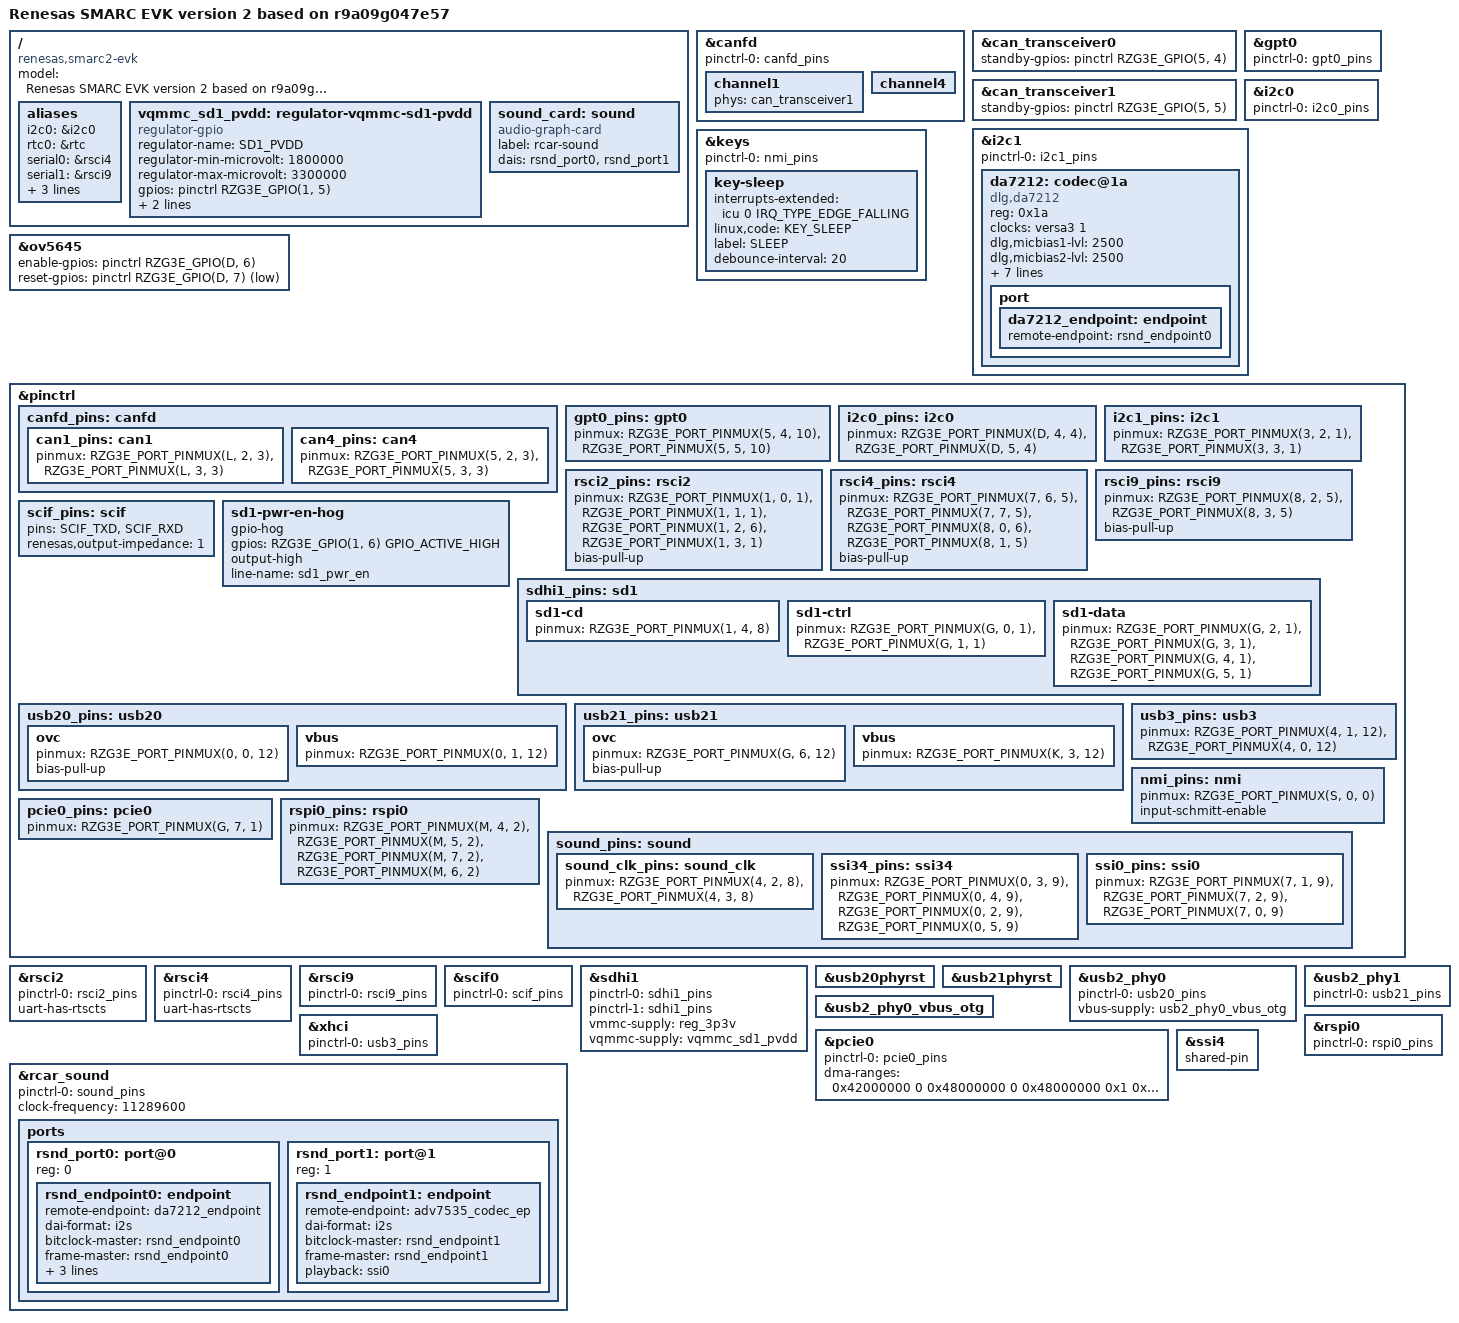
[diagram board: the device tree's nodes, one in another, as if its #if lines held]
// SPDX-License-Identifier: (GPL-2.0-only OR BSD-2-Clause)
/*
 * Device Tree Source for the RZ/G3E SMARC EVK board
 *
 * Copyright (C) 2024 Renesas Electronics Corp.
 */

/dts-v1/;

/* Switch selection settings */
#define SW_GPIO8_CAN0_STB	0
#define SW_GPIO9_CAN1_STB	0
#define SW_LCD_EN		0
#define SW_PDM_EN		0
#define SW_SER0_PMOD           1
#define SW_SER2_EN             1
#define SW_SD0_DEV_SEL		0
#define SW_SDIO_M2E		0
#define SW_HDMI_EN		0

#define PMOD_GPIO4		0
#define PMOD_GPIO6		0
#define PMOD_GPIO7		0

#define KEY_1_GPIO		RZG3E_GPIO(3, 1)
#define KEY_2_GPIO		RZG3E_GPIO(8, 4)
#define KEY_3_GPIO		RZG3E_GPIO(8, 5)

/*
 * Mode selection settings RSPI0_RSCI8_SEL:
 * 1 - RSCI8			0 - RSPI0 (default)
 */

#define RSPI0_RSCI8_SEL		0

/*
 * Display support selection:
 * 0 - disable display selection support
 * 1 - enable display selection support
 * for:
 * - MIPI DSI: RZG3E_SMARC_MIPI_DSI_ENABLE
 * - LVDS: RZG3E_SMARC_LVDS_ENABLE
 * - Parallel RGB: SW_LCD_EN from above switch selection settings
 */

#define RZG3E_SMARC_MIPI_DSI_ENABLE	1
#define RZG3E_SMARC_LVDS_ENABLE 	0

/* Only maximum 2 display selections are enabled at the same time */
#if (RZG3E_SMARC_MIPI_DSI_ENABLE & RZG3E_SMARC_LVDS_ENABLE & SW_LCD_EN)
#error "Only maximum 2 display selections are enabled at the same time"
#endif

#include <dt-bindings/gpio/gpio.h>
#include <dt-bindings/input/input.h>
#include <dt-bindings/pinctrl/renesas,r9a09g047-pinctrl.h>
#include "r9a09g047e57.dtsi"
#include "rzg3e-smarc-som.dtsi"
#include "renesas-smarc2.dtsi"

#define OV5645_PARENT_I2C i2c0
#include "rz-smarc-cru-csi-ov5645.dtsi"

#if (RZG3E_SMARC_LVDS_ENABLE)
#include "renesas-smarc2-dual-lvds-hdmi.dtsi"
#endif
#if (SW_LCD_EN)
#include "renesas-smarc2-rgb.dtsi"
#endif

/*
 * SSI-DA7212
 *
 * These commands are required when Playback/Capture
 *
 *	amixer -q cset name='Aux Switch' on
 *	amixer -q cset name='Mixin Left Aux Left Switch' on
 *	amixer -q cset name='Mixin Right Aux Right Switch' on
 *	amixer -q cset name='ADC Switch' on
 *	amixer -q cset name='Mixout Right Mixin Right Switch' off
 *	amixer -q cset name='Mixout Left Mixin Left Switch' off
 *	amixer -q cset name='Headphone Volume' 80%
 *	amixer -q cset name='Headphone Switch' on
 *	amixer -q cset name='Mixout Left DAC Left Switch' on
 *	amixer -q cset name='Mixout Right DAC Right Switch' on
 *	amixer -q cset name='DAC Left Source MUX' 'DAI Input Left'
 *	amixer -q cset name='DAC Right Source MUX' 'DAI Input Right'
 *	amixer -q sset 'Mic 1 Amp Source MUX' 'MIC_P'
 *	amixer -q sset 'Mic 2 Amp Source MUX' 'MIC_P'
 *	amixer -q sset 'Mixin Left Mic 1' on
 *	amixer -q sset 'Mixin Right Mic 2' on
 *	amixer -q sset 'Mic 1' 80% on
 *	amixer -q sset 'Mic 2' 80% on
 *	amixer -q sset 'Lineout' 80% on
 *	amixer -q sset 'Mixin PGA' 40% on
 *
 * When Capture, use this command to amplify sound
 *	amixer set 'DVC In',0 10%
 *	amixer set 'DVC Out',0 20%
 */

/ {
	model = "Renesas SMARC EVK version 2 based on r9a09g047e57";
	compatible = "renesas,smarc2-evk", "renesas,rzg3e-smarcm",
		     "renesas,r9a09g047e57", "renesas,r9a09g047";

	aliases {
		i2c0 = &i2c0;
		rtc0 = &rtc;
#if (!SW_LCD_EN) && (SW_SER0_PMOD)
		serial0 = &rsci4;
#endif
#if (!SW_LCD_EN)
		serial1 = &rsci9;
#endif
#if SW_SER0_PMOD && SW_SER2_EN
		serial2 = &rsci2;
#endif
		serial3 = &scif0;
		mmc1 = &sdhi1;
	};

	vqmmc_sd1_pvdd: regulator-vqmmc-sd1-pvdd {
		compatible = "regulator-gpio";
		regulator-name = "SD1_PVDD";
		regulator-min-microvolt = <1800000>;
		regulator-max-microvolt = <3300000>;
		gpios = <&pinctrl RZG3E_GPIO(1, 5) GPIO_ACTIVE_HIGH>;
		gpios-states = <0>;
		states = <3300000 0>, <1800000 1>;
	};

#if (SW_PDM_EN)
	codec_test0: codec_test {
		compatible = "linux,snd-soc-dummy";
		#sound-dai-cells = <0>;
		port {
			dummy_codec: endpoint {
				remote-endpoint = <&pdm_endpoint>;
			};
		};
	};
#endif

	sound_card: sound {
		compatible = "audio-graph-card";

		label = "rcar-sound";
		dais = <&rsnd_port0	/* DA7211 */
#if ((!SW_LCD_EN) && (RZG3E_SMARC_MIPI_DSI_ENABLE) && (!SW_HDMI_EN))
			&rsnd_port1	/* HDMI0  */
#endif
#if (SW_PDM_EN)
			&pdm_link
#endif
			>;
	};
};

&canfd {
	pinctrl-0 = <&canfd_pins>;
	pinctrl-names = "default";

#if (!SW_PDM_EN)
	channel1 {
		status = "okay";
#if (!SW_LCD_EN) && (SW_GPIO9_CAN1_STB)
		phys = <&can_transceiver1>;
#endif
	};
#endif

#if (!SW_LCD_EN)
	channel4 {
		status = "okay";
#if (SW_GPIO8_CAN0_STB)
		phys = <&can_transceiver0>;
#endif
	};
#endif
};

#if (!SW_LCD_EN) && (SW_GPIO8_CAN0_STB)
&can_transceiver0 {
	standby-gpios = <&pinctrl RZG3E_GPIO(5, 4) GPIO_ACTIVE_HIGH>;
	status = "okay";
};
#endif

#if (!SW_LCD_EN) && (SW_GPIO9_CAN1_STB)
&can_transceiver1 {
	standby-gpios = <&pinctrl RZG3E_GPIO(5, 5) GPIO_ACTIVE_HIGH>;
	status = "okay";
};
#endif

#if (!SW_LCD_EN) && (!SW_GPIO8_CAN0_STB) && (!SW_GPIO9_CAN1_STB)
&gpt0 {
	pinctrl-0 = <&gpt0_pins>;
	pinctrl-names = "default";
	status = "okay";
};
#endif

&i2c0 {
	pinctrl-0 = <&i2c0_pins>;
	pinctrl-names = "default";
};

&i2c1 {
	pinctrl-0 = <&i2c1_pins>;
	pinctrl-names = "default";

	status = "okay";

	da7212: codec@1a {
		compatible = "dlg,da7212";
		#sound-dai-cells = <0>;
		#address-cells = <1>;
		#size-cells = <0>;
		reg = <0x1a>;

		clocks = <&versa3 1>;
		clock-names = "mclk";

		dlg,micbias1-lvl = <2500>;
		dlg,micbias2-lvl = <2500>;
		dlg,dmic-data-sel = "lrise_rfall";
		dlg,dmic-samplephase = "between_clkedge";
		dlg,dmic-clkrate = <3000000>;

		VDDA-supply = <&reg_1p8v>;
		VDDSP-supply = <&reg_3p3v>;
		VDDMIC-supply = <&reg_3p3v>;
		VDDIO-supply = <&reg_1p8v>;

		port {
			da7212_endpoint: endpoint {
				remote-endpoint = <&rsnd_endpoint0>;
			};
		};
	};
};

&ov5645 {
	enable-gpios = <&pinctrl RZG3E_GPIO(D, 6) GPIO_ACTIVE_HIGH>;
	reset-gpios = <&pinctrl RZG3E_GPIO(D, 7) GPIO_ACTIVE_LOW>;
};

&keys {
	pinctrl-0 = <&nmi_pins>;
	pinctrl-names = "default";

	key-sleep {
		interrupts-extended = <&icu 0 IRQ_TYPE_EDGE_FALLING>;
		linux,code = <KEY_SLEEP>;
		label = "SLEEP";
		debounce-interval = <20>;
	};
#if PMOD_GPIO4
	/delete-node/ key-1;
#endif

#if SW_LCD_EN || PMOD_GPIO6
	/delete-node/ key-2;
#endif

#if SW_LCD_EN || PMOD_GPIO7
	/delete-node/ key-3;
#endif
};

&pinctrl {
	canfd_pins: canfd {
#if (!SW_PDM_EN)
		can1_pins: can1 {
			pinmux = <RZG3E_PORT_PINMUX(L, 2, 3)>, /* RX */
				 <RZG3E_PORT_PINMUX(L, 3, 3)>; /* TX */
		};
#endif

#if (!SW_LCD_EN)
		can4_pins: can4 {
			pinmux = <RZG3E_PORT_PINMUX(5, 2, 3)>, /* RX */
				 <RZG3E_PORT_PINMUX(5, 3, 3)>; /* TX */
		};
#endif
	};

#if (!SW_LCD_EN)
	gpt0_pins: gpt0 {
		pinmux = <RZG3E_PORT_PINMUX(5, 4, 10)>, /* GTIOC4A */
			 <RZG3E_PORT_PINMUX(5, 5, 10)>; /* GTIOC4B */
	};
#endif

	i2c0_pins: i2c0 {
		pinmux = <RZG3E_PORT_PINMUX(D, 4, 4)>, /* SCL0 */
			 <RZG3E_PORT_PINMUX(D, 5, 4)>; /* SDA0 */
	};

	i2c1_pins: i2c1 {
		pinmux = <RZG3E_PORT_PINMUX(3, 2, 1)>, /* SCL1 */
			 <RZG3E_PORT_PINMUX(3, 3, 1)>; /* SDA1 */
	};

#if SW_SER0_PMOD && SW_SER2_EN
	rsci2_pins: rsci2 {
		pinmux = <RZG3E_PORT_PINMUX(1, 0, 1)>, /* RXD2 */
			 <RZG3E_PORT_PINMUX(1, 1, 1)>, /* TXD2 */
			 <RZG3E_PORT_PINMUX(1, 2, 6)>, /* CTS2N */
			 <RZG3E_PORT_PINMUX(1, 3, 1)>; /* RTS2N */
		bias-pull-up;
	};
#endif

#if (!SW_LCD_EN) && (SW_SER0_PMOD)
	rsci4_pins: rsci4 {
		pinmux = <RZG3E_PORT_PINMUX(7, 6, 5)>, /* RXD4 */
			 <RZG3E_PORT_PINMUX(7, 7, 5)>, /* TXD4 */
			 <RZG3E_PORT_PINMUX(8, 0, 6)>, /* CTS4N */
			 <RZG3E_PORT_PINMUX(8, 1, 5)>; /* RTS4N */
		bias-pull-up;
	};
#endif

#if (!SW_LCD_EN)
	rsci9_pins: rsci9 {
		pinmux = <RZG3E_PORT_PINMUX(8, 2, 5)>, /* RXD9 */
			 <RZG3E_PORT_PINMUX(8, 3, 5)>; /* TXD9 */
		bias-pull-up;
	};
#endif

	scif_pins: scif {
		pins = "SCIF_TXD", "SCIF_RXD";
		renesas,output-impedance = <1>;
	};

	sd1-pwr-en-hog {
		gpio-hog;
		gpios = <RZG3E_GPIO(1, 6) GPIO_ACTIVE_HIGH>;
		output-high;
		line-name = "sd1_pwr_en";
	};

	sdhi1_pins: sd1 {
		sd1-cd {
			pinmux = <RZG3E_PORT_PINMUX(1, 4, 8)>; /* SD1CD */
		};

		sd1-ctrl {
			pinmux = <RZG3E_PORT_PINMUX(G, 0, 1)>, /* SD1CLK */
				 <RZG3E_PORT_PINMUX(G, 1, 1)>; /* SD1CMD */
		};

		sd1-data {
			pinmux = <RZG3E_PORT_PINMUX(G, 2, 1)>, /* SD1DAT0 */
				 <RZG3E_PORT_PINMUX(G, 3, 1)>, /* SD1DAT1 */
				 <RZG3E_PORT_PINMUX(G, 4, 1)>, /* SD1DAT2 */
				 <RZG3E_PORT_PINMUX(G, 5, 1)>; /* SD1DAT3 */
		};
	};

	usb20_pins: usb20 {
		ovc {
			pinmux =  <RZG3E_PORT_PINMUX(0, 0, 12)>; /* OVC */
			bias-pull-up;
		};

		vbus {
			pinmux = <RZG3E_PORT_PINMUX(0, 1, 12)>; /* VBUS */
		};
	};

	usb21_pins: usb21 {
		ovc {
			pinmux = <RZG3E_PORT_PINMUX(G, 6, 12)>; /* OVC */
			bias-pull-up;
		};

		vbus {
			pinmux = <RZG3E_PORT_PINMUX(K, 3, 12)>; /* VBUS */
		};
	};

	usb3_pins: usb3 {
		pinmux = <RZG3E_PORT_PINMUX(4, 1, 12)>, /* USB30_VBUSEN */
			 <RZG3E_PORT_PINMUX(4, 0, 12)>; /* USB30_OVRCURN */
	};

	nmi_pins: nmi {
		pinmux = <RZG3E_PORT_PINMUX(S, 0, 0)>; /* NMI */
		input-schmitt-enable;
	};

	pcie0_pins: pcie0 {
		pinmux = <RZG3E_PORT_PINMUX(G, 7, 1)>; /* PCIE_SLOT_RST */
	};

#if (!RSPI0_RSCI8_SEL)
	rspi0_pins: rspi0 {
		pinmux = <RZG3E_PORT_PINMUX(M, 4, 2)>, /* MISOA */
			 <RZG3E_PORT_PINMUX(M, 5, 2)>, /* MOSIA */
			 <RZG3E_PORT_PINMUX(M, 7, 2)>, /* SSLA0 */
			 <RZG3E_PORT_PINMUX(M, 6, 2)>; /* RSPCKA */
	};
#else
	rsci8_master_pins: rscri8_master {
		pinmux = <RZG3E_PORT_PINMUX(M, 5, 5)>, /* SCI8_TXD_MOSI_SDA */
			 <RZG3E_PORT_PINMUX(M, 4, 5)>, /* SCI8_RXD_MISO_SCL */
			 <RZG3E_PORT_PINMUX(M, 6, 5)>; /* SCI8_SCLK */
	};
#endif

	sound_pins: sound {
		sound_clk_pins: sound_clk {
			pinmux = <RZG3E_PORT_PINMUX(4, 2, 8)>, /* AUDIO_CLKB */
				 <RZG3E_PORT_PINMUX(4, 3, 8)>; /* AUDIO_CLKC */
		};

		ssi34_pins: ssi34 {
			pinmux = <RZG3E_PORT_PINMUX(0, 3, 9)>, /* SSI3_SCK */
				 <RZG3E_PORT_PINMUX(0, 4, 9)>, /* SSI3_WS */
				 <RZG3E_PORT_PINMUX(0, 2, 9)>, /* SSI3_SDATA */
				 <RZG3E_PORT_PINMUX(0, 5, 9)>; /* SSI4_SDATA */
		};

#if (!SW_LCD_EN)
		ssi0_pins: ssi0 {
			pinmux = <RZG3E_PORT_PINMUX(7, 1, 9)>, /* SSI0_SCK */
				 <RZG3E_PORT_PINMUX(7, 2, 9)>, /* SSI0_WS */
				 <RZG3E_PORT_PINMUX(7, 0, 9)>; /* SSI0_SDATA */
		};
#endif
	};

#if (SW_PDM_EN)
	pdm0_pins: pdm0 {
		pinmux = <RZG3E_PORT_PINMUX(L, 2, 7)>, /* PDMCLK01 */
			 <RZG3E_PORT_PINMUX(L, 3, 7)>; /* PDMDAT01 */
	};

#endif
};

#if SW_SER0_PMOD && SW_SER2_EN
&rsci2 {
	pinctrl-0 = <&rsci2_pins>;
	pinctrl-names = "default";

	uart-has-rtscts;

	status = "okay";
};
#endif

#if (!SW_LCD_EN) && (SW_SER0_PMOD)
&rsci4 {
	pinctrl-0 = <&rsci4_pins>;
	pinctrl-names = "default";

	uart-has-rtscts;

	status = "okay";
};
#endif

#if (!SW_LCD_EN)
&rsci9 {
	pinctrl-0 = <&rsci9_pins>;
	pinctrl-names = "default";

	status = "okay";
};
#endif

&scif0 {
	pinctrl-0 = <&scif_pins>;
	pinctrl-names = "default";
};

&sdhi1 {
	pinctrl-0 = <&sdhi1_pins>;
	pinctrl-1 = <&sdhi1_pins>;
	pinctrl-names = "default", "state_uhs";

	vmmc-supply = <&reg_3p3v>;
	vqmmc-supply = <&vqmmc_sd1_pvdd>;
};

&usb20phyrst {
	status = "okay";
};

&usb21phyrst {
	status = "okay";
};

&usb2_phy0 {
	pinctrl-0 = <&usb20_pins>;
	pinctrl-names = "default";

	vbus-supply = <&usb2_phy0_vbus_otg>;
	status = "okay";
};

&usb2_phy0_vbus_otg {
	status = "okay";
};

&usb2_phy1 {
	pinctrl-0 = <&usb21_pins>;
	pinctrl-names = "default";

	status = "okay";
};

&xhci {
	pinctrl-0 = <&usb3_pins>;
	pinctrl-names = "default";
};

&pcie0 {
	pinctrl-0 = <&pcie0_pins>;
	pinctrl-names = "default";
	status = "okay";

	/* First 128MB is reserved for secure area. */
	dma-ranges = <0x42000000 0 0x48000000 0 0x48000000 0x1 0xF8000000>;
};

#if (!RSPI0_RSCI8_SEL)
&rspi0 {
	pinctrl-0 = <&rspi0_pins>;
	pinctrl-names = "default";

	status = "okay";
};
#else
&rsci8 {
	pinctrl-0 = <&rsci8_master_pins>;
	pinctrl-names = "master";

	status = "okay";

	renesas,rsci_spi;
	num-cs = <1>;
	#size-cells = <0>;
	#address-cells = <1>;
	/* Using cs-gpios property when is master mode */
	cs-gpios = <&pinctrl RZG3E_GPIO(M, 7) GPIO_ACTIVE_HIGH>;
};
#endif

&rcar_sound {
	pinctrl-0 = <&sound_pins>;
	pinctrl-names = "default";

	status = "okay";

	/* audio_clkout */
	#clock-cells = <0>;
	clock-frequency = <11289600>;

	/* Multi DAI */
	#sound-dai-cells = <1>;

	ports {
		#address-cells = <1>;
		#size-cells = <0>;

		rsnd_port0: port@0 {
			reg = <0>;
			rsnd_endpoint0: endpoint {
				remote-endpoint = <&da7212_endpoint>;

				dai-format = "i2s";
				bitclock-master = <&rsnd_endpoint0>;
				frame-master = <&rsnd_endpoint0>;
				mclk-fs = <512>;

				playback = <&ssi3>, <&src0>, <&dvc0>;
				capture = <&ssi4>, <&src1>, <&dvc1>;
			};
		};

#if ((!SW_LCD_EN) && (RZG3E_SMARC_MIPI_DSI_ENABLE) && (!SW_HDMI_EN))
		rsnd_port1: port@1 {
			reg = <1>;
			rsnd_endpoint1: endpoint {
				remote-endpoint = <&adv7535_codec_ep>;
				dai-format = "i2s";
				bitclock-master = <&rsnd_endpoint1>;
				frame-master = <&rsnd_endpoint1>;

				playback = <&ssi0>;
			};
		};
#endif
	};
};

#if (SW_PDM_EN)
&pdm0 {
	pinctrl-0 = <&pdm0_pins>;
	pinctrl-names = "default";
	status = "okay";

	pdm_link: port {
		pdm_endpoint: endpoint {
			remote-endpoint = <&dummy_codec>;
		};
	};

	channel1 {
		status = "okay";
	};
};
#endif

&ssi4 {
	shared-pin;
};
